# f29h85x_hsm_dmt1_regs register map
Vendor: Texas Instruments
Peripheral module from a debugger description file (folder HSM).
Registers are 32-bit, read-write, no defined reset value unless marked. A register's access mark holds for its fields unless they carry their own. Offsets are as the file gives them; lines under a group give offsets from that group; [hi:lo] are bit positions; {n}, {i} and the like mark numbered series; 'fields as' and 'values as' point back to an identical list; <NAME> marks a mode.

## HSM_DMT1 — HSM DMT1 Registers
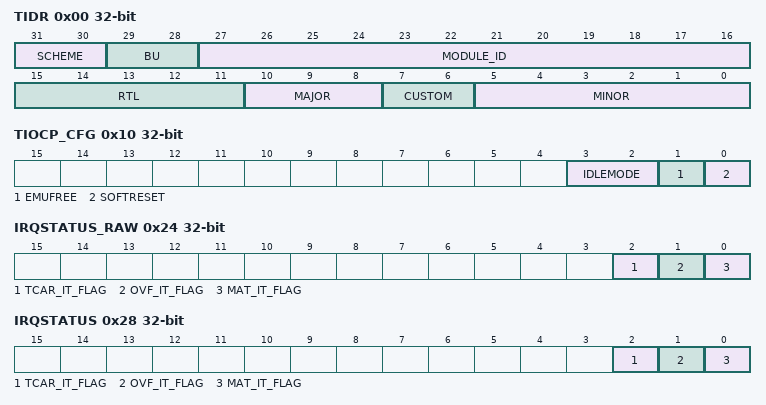
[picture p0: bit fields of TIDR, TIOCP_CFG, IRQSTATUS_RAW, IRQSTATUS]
0x00 TIDR ro — Peripheral ID
  [31:30] SCHEME, [29:28] BU, [27:16] MODULE_ID, [15:11] RTL, [10:8] MAJOR, [7:6] CUSTOM, [5:0] MINOR
0x10 TIOCP_CFG — OCP Control
  [3:2] IDLEMODE, [1] EMUFREE, [0] SOFTRESET
0x20 IRQ_EOI — SW End Of Interrupt
  [0] LINE_NUMBER
0x24 IRQSTATUS_RAW — Interrupt Status - Raw
  [2] TCAR_IT_FLAG, [1] OVF_IT_FLAG, [0] MAT_IT_FLAG
0x28 IRQSTATUS — Interrupt Status
  [2] TCAR_IT_FLAG, [1] OVF_IT_FLAG, [0] MAT_IT_FLAG
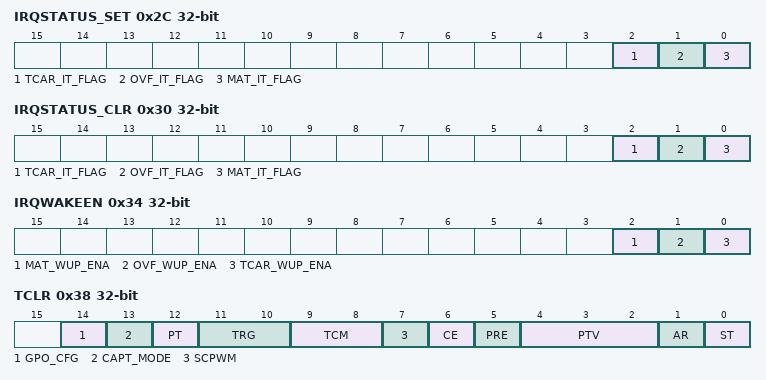
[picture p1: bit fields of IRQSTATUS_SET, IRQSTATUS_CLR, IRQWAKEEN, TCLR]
0x2C IRQSTATUS_SET
  [2] TCAR_IT_FLAG, [1] OVF_IT_FLAG, [0] MAT_IT_FLAG
0x30 IRQSTATUS_CLR
  [2] TCAR_IT_FLAG, [1] OVF_IT_FLAG, [0] MAT_IT_FLAG
0x34 IRQWAKEEN
  [2] MAT_WUP_ENA, [1] OVF_WUP_ENA, [0] TCAR_WUP_ENA
0x38 TCLR
  [14] GPO_CFG, [13] CAPT_MODE, [12] PT, [11:10] TRG, [9:8] TCM, [7] SCPWM, [6] CE, [5] PRE, [4:2] PTV, [1] AR, [0] ST
0x3C TCRR
  [31:0] TIMER_COUNTER
0x40 TLDR
  [31:0] LOAD_VALUE
0x44 TTGR
  [31:0] TTRG_VLAUE
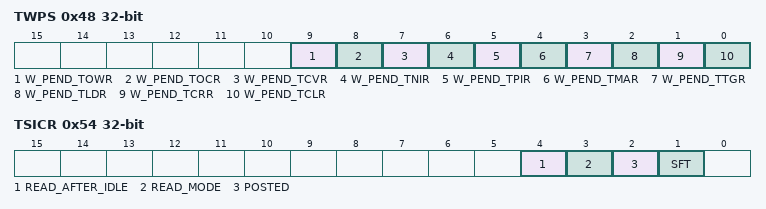
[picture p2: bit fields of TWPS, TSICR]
0x48 TWPS ro
  [9] W_PEND_TOWR, [8] W_PEND_TOCR, [7] W_PEND_TCVR, [6] W_PEND_TNIR, [5] W_PEND_TPIR, [4] W_PEND_TMAR, [3] W_PEND_TTGR, [2] W_PEND_TLDR, [1] W_PEND_TCRR, [0] W_PEND_TCLR
0x4C TMAR
  [31:0] COMPARE_VLAUE
0x50 TCAR1 ro
  [31:0] CAPTURE_VALUE1
0x54 TSICR
  [4] READ_AFTER_IDLE, [3] READ_MODE, [2] POSTED, [1] SFT
0x58 TCAR2 ro
  [31:0] CAPTURE_VALUE2
0x5C TPIR
  [31:0] POSITIVE_INC_VALUE
0x60 TNIR
  [31:0] NEGATIVE_INC_VALUE
0x64 TCVR
  [31:0] COUNTER_VALUE
0x68 TOCR
  [23:0] OVF_COUNTER_VALUE
0x6C TOWR
  [23:0] OVF_WRAPPING_VALUE
